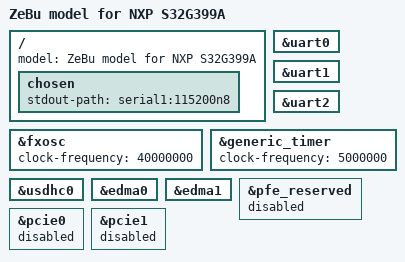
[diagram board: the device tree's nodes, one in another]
// SPDX-License-Identifier: GPL-2.0
/*
 * Copyright 2021-2022 NXP
 *
 * This program is free software; you can redistribute it and/or modify
 * it under the terms of the GNU General Public License as published by
 * the Free Software Foundation; either version 2 of the License, or
 * (at your option) any later version.
 */

/dts-v1/;
#include "fsl-s32g3.dtsi"

/* Emulator has 1GB of RAM, remove reserved memory above this limit */
/delete-node/ &pci_shared_memory0;
/delete-node/ &pci_shared_memory1;

/ {
	model = "ZeBu model for NXP S32G399A";

	chosen {
		stdout-path = "serial1:115200n8";
	};
};

&uart0 {
	/delete-property/ dmas;
	/delete-property/ dma-names;
};

&uart1 {
	/delete-property/ dmas;
	/delete-property/ dma-names;
};

&uart2 {
	/delete-property/ dmas;
	/delete-property/ dma-names;
};

&fxosc {
	clock-frequency = <40000000>;
};

&generic_timer {
	clock-frequency = <5000000>;
};

&usdhc0 {
	status = "okay";
};

&edma0 {
	status = "okay";
};

&edma1 {
	status = "okay";
};

&pfe_reserved  {
	status = "disabled";
};

&pcie0 {
	/delete-property/ shared-mem;
	status = "disabled";
};

&pcie1 {
	/delete-property/ shared-mem;
	status = "disabled";
};
